# XHSC_HC32F175 register map
Vendor: XHSC Co.Ltd; Series: ARMCM0P; File version: 1.0
CPU: CM0P r0p0, little endian, no MPU, no FPU, 3 interrupt priority bits
Registers are 32-bit, read-write, reset 0x0 unless marked. A register's access mark holds for its fields unless they carry their own. Offsets are from the block's base; [hi:lo] are bit positions; {n}, {i} and the like mark numbered series; 'fields as' and 'values as' point back to an identical list.

## CRC
Base 0x40027800
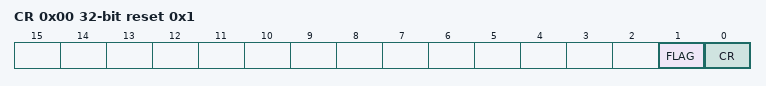
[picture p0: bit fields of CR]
0x00 CR reset 0x1
  [1] FLAG ro, [0] CR
0x04 RESULT
0x80 DATA wo

## CSU0 — desc CSU
Base 0x40025100
Same registers: CSU1 0x40025120, CSU2 0x40025140
0x00 CR
  [0] CSE
0x04 LVR
  [15:0] LVR
0x08 UVR
  [12:0] UVR
0x0C CNTR ro
  [15:0] CNTR
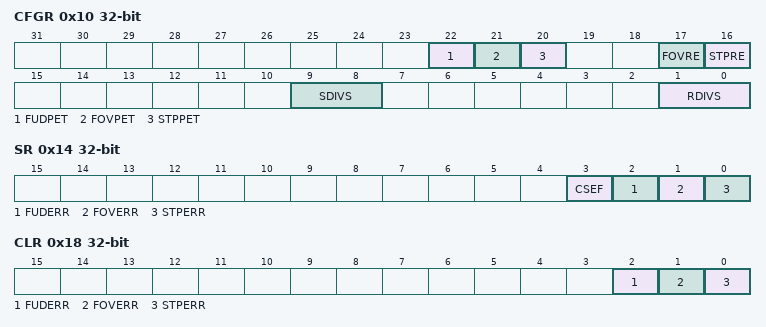
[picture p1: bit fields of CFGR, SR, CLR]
0x10 CFGR
  [22] FUDPET, [21] FOVPET, [20] STPPET, [17] FOVRE, [16] STPRE, [9:8] SDIVS, [1:0] RDIVS
0x14 SR ro reset not defined
  [3] CSEF, [2] FUDERR, [1] FOVERR, [0] STPERR
0x18 CLR wo
  [2] FUDERR, [1] FOVERR, [0] STPERR

## CTRIM
Base 0x40000000
0x00 ARR reset 0xFFFF
  [15:0] ARR
0x04 CNT ro
  [15:0] CNT
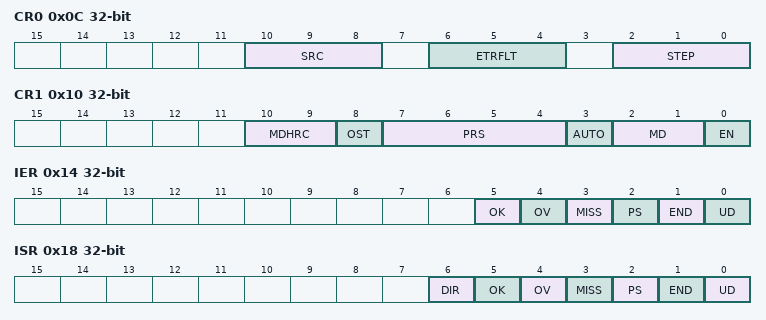
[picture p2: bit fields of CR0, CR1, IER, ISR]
0x0C CR0
  [10:8] SRC, [6:4] ETRFLT, [2:0] STEP
0x10 CR1 (reset mask 0x1FF)
  [10:9] MDHRC, [8] OST, [7:4] PRS, [3] AUTO, [2:1] MD, [0] EN
0x14 IER
  [5] OK, [4] OV, [3] MISS, [2] PS, [1] END, [0] UD
0x18 ISR ro
  [6] DIR, [5] OK, [4] OV, [3] MISS, [2] PS, [1] END, [0] UD
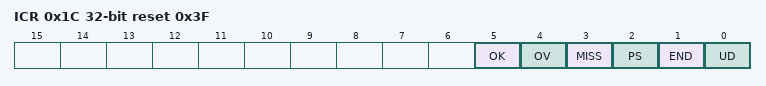
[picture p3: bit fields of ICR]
0x1C ICR wo reset 0x3F
  [5] OK, [4] OV, [3] MISS, [2] PS, [1] END, [0] UD
0x20 FCAP ro reset 0xFFFF
  [15:0] FCAP
0x24 TVAL ro reset 0x100
  [15:0] TVAL
0x28 FLIM reset 0x10
  [11:0] FLIM

## DBGC
Base 0x40001C00
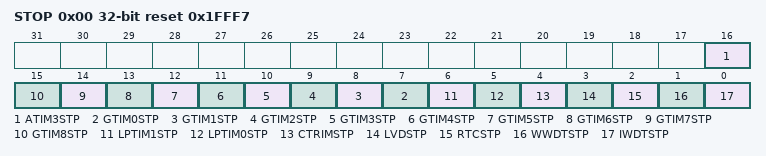
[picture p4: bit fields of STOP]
0x00 STOP reset 0x1FFF7
  [16] ATIM3STP, [n+7] GTIM{n}STP (n=0..8), [6] LPTIM1STP, [5] LPTIM0STP, [4] CTRIMSTP, [3] LVDSTP, [2] RTCSTP, [1] WWDTSTP, [0] IWDTSTP

## DFM
Base 0x40026800
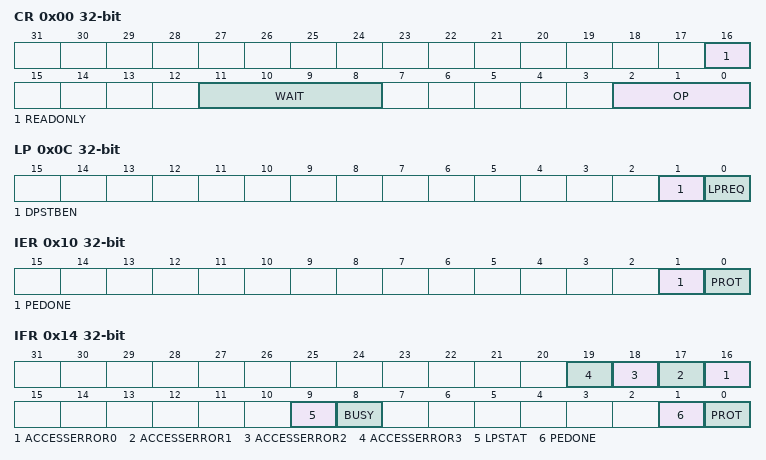
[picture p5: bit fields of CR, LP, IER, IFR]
0x00 CR
  [16] READONLY, [11:8] WAIT, [2:0] OP
0x0C LP
  [1] DPSTBEN, [0] LPREQ wo
0x10 IER
  [1] PEDONE, [0] PROT
0x14 IFR ro
  [n+16] ACCESSERROR{n} (n=0..3), [9] LPSTAT, [8] BUSY, [1] PEDONE, [0] PROT
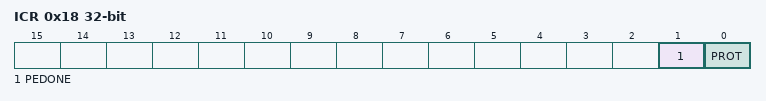
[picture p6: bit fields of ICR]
0x18 ICR wo
  [1] PEDONE, [0] PROT
0x2C BYPASS wo
  [15:0] BYSEQ
{0x30+4i} SLOCK{i} reset 0xFFFFFFFF (i=0..3)
  [31:0] SLOCK

## DMAC
Base 0x40024800
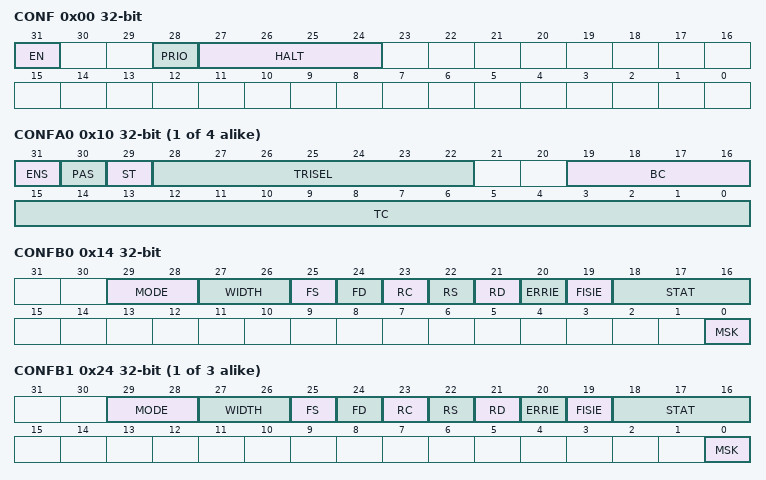
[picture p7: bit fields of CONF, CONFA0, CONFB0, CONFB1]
0x00 CONF
  [31] EN, [28] PRIO, [27:24] HALT
{0x10+0x10*i} CONFA{i} (i=0..3)
  [31] ENS, [30] PAS, [29] ST, [28:22] TRISEL, [19:16] BC, [15:0] TC
0x14 CONFB0 (reset mask 0x3FFF001)
  [29:28] MODE, [27:26] WIDTH, [25] FS, [24] FD, [23] RC, [22] RS, [21] RD, [20] ERRIE, [19] FISIE, [18:16] STAT, [0] MSK
{0x18+0x10*i} SRCADR{i} (i=0..3)
  [31:0] SRCADR
{0x1C+0x10*i} DSTADR{i} (i=0..3)
  [31:0] DSTADR
{0x14+0x10*i} CONFB{i} (i=1..3)
  fields as CONFB0

## EFM
Base 0x40026400
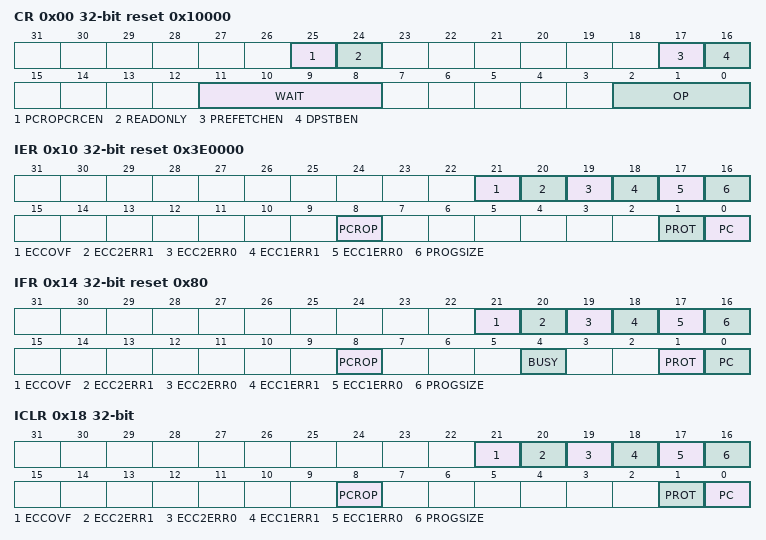
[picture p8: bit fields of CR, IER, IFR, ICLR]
0x00 CR reset 0x10000
  [25] PCROPCRCEN, [24] READONLY, [17] PREFETCHEN, [16] DPSTBEN, [11:8] WAIT, [2:0] OP
0x10 IER reset 0x3E0000
  [21] ECCOVF, [20] ECC2ERR1, [19] ECC2ERR0, [18] ECC1ERR1, [17] ECC1ERR0, [16] PROGSIZE, [8] PCROP, [1] PROT, [0] PC
0x14 IFR ro reset 0x80
  [21] ECCOVF, [20] ECC2ERR1, [19] ECC2ERR0, [18] ECC1ERR1, [17] ECC1ERR0, [16] PROGSIZE, [8] PCROP, [4] BUSY, [1] PROT, [0] PC
0x18 ICLR wo
  fields as IER
0x2C BYPASS
  [15:0] BYSEQ
{0x30+4i} SLOCK{i} (i=0..7)
  [31:0] SLOCK
0x74 LOCKST ro
  [1:0] STATE
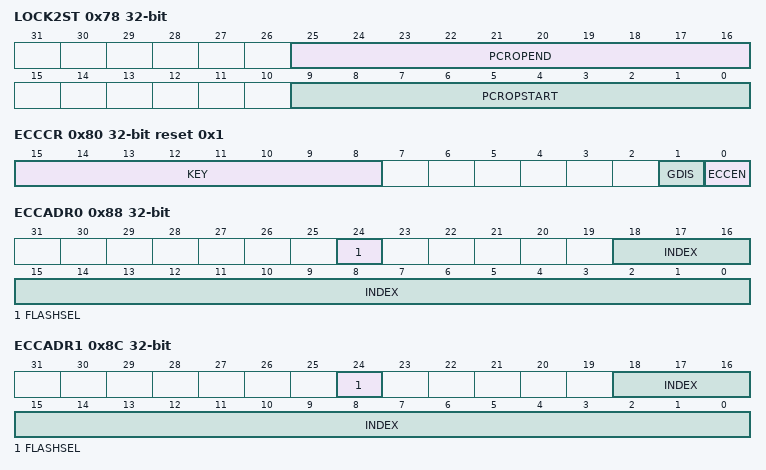
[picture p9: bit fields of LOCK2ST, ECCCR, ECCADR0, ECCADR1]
0x78 LOCK2ST ro
  [25:16] PCROPEND, [9:0] PCROPSTART
0x80 ECCCR reset 0x1
  [15:8] KEY wo, [1] GDIS, [0] ECCEN
0x84 ECCDR
  [7:0] ECCWD
0x88 ECCADR0 ro (reset mask 0x7FFFF)
  [24] FLASHSEL, [18:0] INDEX
0x8C ECCADR1 ro (reset mask 0x7FFFF)
  [24] FLASHSEL, [18:0] INDEX

## EXTI
Base 0x40024000
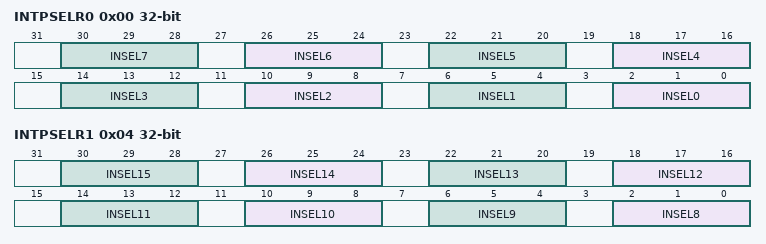
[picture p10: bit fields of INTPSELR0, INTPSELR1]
0x00 INTPSELR0
  [4n+2:4n] INSEL{n} (n=0..7)
0x04 INTPSELR1
  [4n-30:4n-32] INSEL{n} (n=8..15)
0x10 INTPDFLTCR
  [0] CLKSEL
0x14 INTPDFLTER
  [15:0] EN
0x18 INTPIESELR
  [15:0] IESEL
0x1C INTPHIEER
  [15:0] EN
0x20 INTPLIEER
  [15:0] EN
0x24 INTPRIEER
  [15:0] EN
0x28 INTPFIEER
  [15:0] EN
0x2C INTPIEFR ro
  [15:0] IEF
0x30 INTPIECLR wo
  [15:0] IECL
0x34 WKUPRIER
  [7:0] EN
0x38 WKUPFIER
  [7:0] EN
0x3C WKUP_IFR ro
  [7:0] IF
0x40 WKUP_ICLR wo
  [7:0] ICL

## GTIM0 — desc GTIM
Base 0x40005800
Same registers: GTIM1 0x40005C00, GTIM2 0x40006000, GTIM3 0x40006400, GTIM4 0x40006800, GTIM5 0x40006C00, GTIM6 0x4000C800, GTIM7 0x4000CC00, GTIM8 0x4000D000
0x00 ARR
  [15:0] ARR
0x04 CNT
  [15:0] CNT
0x08 CNT32
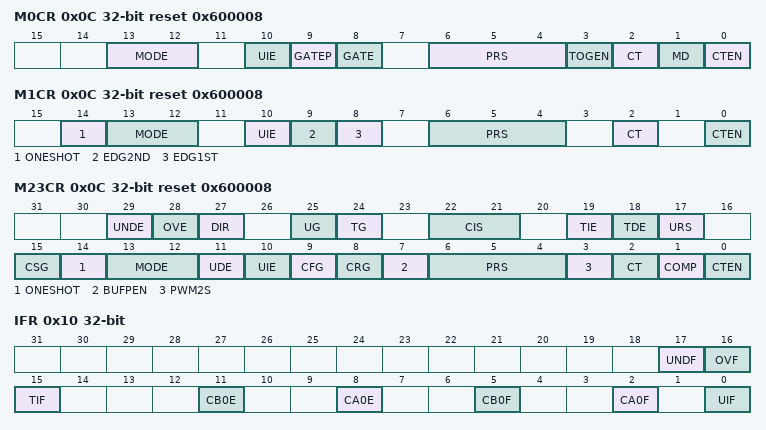
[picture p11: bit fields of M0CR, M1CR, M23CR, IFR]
0x0C M0CR reset 0x600008
  [13:12] MODE, [10] UIE, [9] GATEP, [8] GATE, [6:4] PRS, [3] TOGEN, [2] CT, [1] MD, [0] CTEN
0x0C M1CR reset 0x600008
  [14] ONESHOT, [13:12] MODE, [10] UIE, [9] EDG2ND, [8] EDG1ST, [6:4] PRS, [2] CT, [0] CTEN
0x0C M23CR reset 0x600008
  [29] UNDE, [28] OVE, [27] DIR, [25] UG wo, [24] TG wo, [22:21] CIS, [19] TIE, [18] TDE, [17] URS, [15] CSG, [14] ONESHOT, [13:12] MODE, [11] UDE, [10] UIE, [9] CFG, [8] CRG, [7] BUFPEN, [6:4] PRS, [3] PWM2S, [2] CT, [1] COMP, [0] CTEN
0x10 IFR ro
  [17] UNDF, [16] OVF, [15] TIF, [11] CB0E, [8] CA0E, [5] CB0F, [2] CA0F, [0] UIF
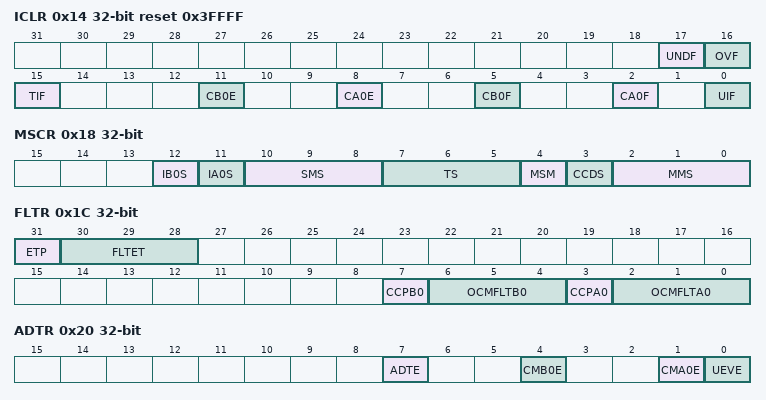
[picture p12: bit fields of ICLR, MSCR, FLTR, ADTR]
0x14 ICLR wo reset 0x3FFFF
  fields as IFR
0x18 MSCR (reset mask 0x7FF)
  [12] IB0S, [11] IA0S, [10:8] SMS, [7:5] TS, [4] MSM, [3] CCDS, [2:0] MMS
0x1C FLTR
  [31] ETP, [30:28] FLTET, [7] CCPB0, [6:4] OCMFLTB0, [3] CCPA0, [2:0] OCMFLTA0
0x20 ADTR
  [7] ADTE, [4] CMB0E, [1] CMA0E, [0] UEVE
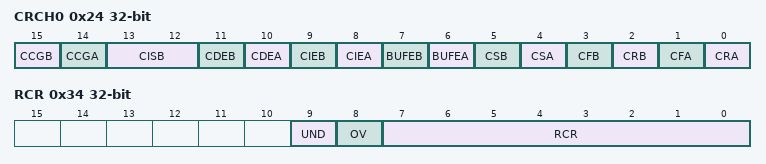
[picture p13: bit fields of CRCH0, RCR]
0x24 CRCH0
  [15] CCGB, [14] CCGA, [13:12] CISB, [11] CDEB, [10] CDEA, [9] CIEB, [8] CIEA, [7] BUFEB, [6] BUFEA, [5] CSB, [4] CSA, [3] CFB, [2] CRB, [1] CFA, [0] CRA
0x34 RCR
  [9] UND, [8] OV, [7:0] RCR
0x38 ARRDM
  [15:0] ARRDM
0x3C CCR0A
  [15:0] CCR0A
0x40 CCR0B
  [15:0] CCR0B
